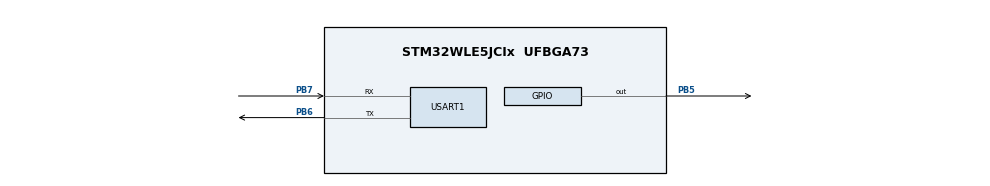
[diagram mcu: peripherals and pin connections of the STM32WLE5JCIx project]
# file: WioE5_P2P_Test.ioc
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Mcu.Family=STM32WL
Mcu.Name=STM32WLE5JCIx
Mcu.Package=UFBGA73
NVIC.PriorityGroup=NVIC_PRIORITYGROUP_4
NVIC.USART1_IRQn=true\:0\:0\:false\:false\:true\:true\:true\:true
PA13.Signal=DEBUG_JTMS-SWDIO
PA14.Signal=DEBUG_JTCK-SWCLK
PB5.Signal=GPIO_Output
PB6.Mode=Asynchronous
PB6.Signal=USART1_TX
PB7.Mode=Asynchronous
PB7.Signal=USART1_RX
ProjectManager.HeapSize=0x200
ProjectManager.StackSize=0x400
ProjectManager.TargetToolchain=STM32CubeIDE
RCC.HSE_VALUE=8000000
RCC.HSI_VALUE=16000000
RCC.LSE_VALUE=32768
RCC.VCOOutputFreq_Value=32000000
USART1.VirtualMode-Asynchronous=VM_ASYNC
board=custom

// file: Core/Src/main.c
/* USER CODE BEGIN Header */
/**
 ******************************************************************************
 * @file           : main.c
 * @brief          : Main program body
 ******************************************************************************
 * @attention
 *
 * Copyright (c) 2025 STMicroelectronics.
 * All rights reserved.
 *
 * This software is licensed under terms that can be found in the LICENSE file
 * in the root directory of this software component.
 * If no LICENSE file comes with this software, it is provided AS-IS.
 *
 ******************************************************************************
 */
/* USER CODE END Header */
#include "main.h"

UART_HandleTypeDef huart1;

/* USER CODE BEGIN PV */
uint8_t rx_data; // UARTで受信した1バイトのデータを格納する変数
/* USER CODE END PV */

void SystemClock_Config(void);
static void MX_GPIO_Init(void);
static void MX_USART1_UART_Init(void);

int main(void) {

	/* MCU Configuration--------------------------------------------------------*/

	/* Reset of all peripherals, Initializes the Flash interface and the Systick. */
	HAL_Init();

	/* Configure the system clock */
	SystemClock_Config();

	/* Initialize all configured peripherals */
	MX_GPIO_Init();
	MX_USART1_UART_Init();
	/* USER CODE BEGIN 2 */
	// 最初に一度だけ、UARTの割り込み受信を開始する
	HAL_UART_Receive_IT(&huart1, &rx_data, 1);
	/* USER CODE END 2 */

	/* Infinite loop */
	while (1) {
		HAL_GPIO_TogglePin(GPIOB, GPIO_PIN_5);
		// 1秒待つ
		HAL_Delay(500);
	}
}

void SystemClock_Config(void) {
	RCC_OscInitTypeDef RCC_OscInitStruct = { 0 };
	RCC_ClkInitTypeDef RCC_ClkInitStruct = { 0 };

	/** Configure the main internal regulator output voltage
	 */
	__HAL_PWR_VOLTAGESCALING_CONFIG(PWR_REGULATOR_VOLTAGE_SCALE2);

	/** Initializes the CPU, AHB and APB buses clocks
	 */
	RCC_OscInitStruct.OscillatorType = RCC_OSCILLATORTYPE_MSI;
	RCC_OscInitStruct.MSIState = RCC_MSI_ON;
	RCC_OscInitStruct.MSICalibrationValue = RCC_MSICALIBRATION_DEFAULT;
	RCC_OscInitStruct.MSIClockRange = RCC_MSIRANGE_6;
	RCC_OscInitStruct.PLL.PLLState = RCC_PLL_NONE;
	if (HAL_RCC_OscConfig(&RCC_OscInitStruct) != HAL_OK) {
		Error_Handler();
	}

	/** Configure the SYSCLKSource, HCLK, PCLK1 and PCLK2 clocks dividers
	 */
	RCC_ClkInitStruct.ClockType = RCC_CLOCKTYPE_HCLK3 | RCC_CLOCKTYPE_HCLK
			| RCC_CLOCKTYPE_SYSCLK | RCC_CLOCKTYPE_PCLK1 | RCC_CLOCKTYPE_PCLK2;
	RCC_ClkInitStruct.SYSCLKSource = RCC_SYSCLKSOURCE_MSI;
	RCC_ClkInitStruct.AHBCLKDivider = RCC_SYSCLK_DIV1;
	RCC_ClkInitStruct.APB1CLKDivider = RCC_HCLK_DIV1;
	RCC_ClkInitStruct.APB2CLKDivider = RCC_HCLK_DIV1;
	RCC_ClkInitStruct.AHBCLK3Divider = RCC_SYSCLK_DIV1;

	if (HAL_RCC_ClockConfig(&RCC_ClkInitStruct, FLASH_LATENCY_0) != HAL_OK) {
		Error_Handler();
	}
}

static void MX_USART1_UART_Init(void) {

	huart1.Instance = USART1;
	huart1.Init.BaudRate = 115200;
	huart1.Init.WordLength = UART_WORDLENGTH_8B;
	huart1.Init.StopBits = UART_STOPBITS_1;
	huart1.Init.Parity = UART_PARITY_NONE;
	huart1.Init.Mode = UART_MODE_TX_RX;
	huart1.Init.HwFlowCtl = UART_HWCONTROL_NONE;
	huart1.Init.OverSampling = UART_OVERSAMPLING_16;
	huart1.Init.OneBitSampling = UART_ONE_BIT_SAMPLE_DISABLE;
	huart1.Init.ClockPrescaler = UART_PRESCALER_DIV1;
	huart1.AdvancedInit.AdvFeatureInit = UART_ADVFEATURE_NO_INIT;
	if (HAL_UART_Init(&huart1) != HAL_OK) {
		Error_Handler();
	}
	if (HAL_UARTEx_SetTxFifoThreshold(&huart1, UART_TXFIFO_THRESHOLD_1_8)
			!= HAL_OK) {
		Error_Handler();
	}
	if (HAL_UARTEx_SetRxFifoThreshold(&huart1, UART_RXFIFO_THRESHOLD_1_8)
			!= HAL_OK) {
		Error_Handler();
	}
	if (HAL_UARTEx_DisableFifoMode(&huart1) != HAL_OK) {
		Error_Handler();
	}

}

static void MX_GPIO_Init(void) {
	GPIO_InitTypeDef GPIO_InitStruct = { 0 };

	/* GPIO Ports Clock Enable */
	__HAL_RCC_GPIOA_CLK_ENABLE();
	__HAL_RCC_GPIOB_CLK_ENABLE();

	/*Configure GPIO pin Output Level */
	HAL_GPIO_WritePin(GPIOB, GPIO_PIN_5, GPIO_PIN_RESET);

	/*Configure GPIO pin : PB5 */
	GPIO_InitStruct.Pin = GPIO_PIN_5;
	GPIO_InitStruct.Mode = GPIO_MODE_OUTPUT_PP;
	GPIO_InitStruct.Pull = GPIO_NOPULL;
	GPIO_InitStruct.Speed = GPIO_SPEED_FREQ_LOW;
	HAL_GPIO_Init(GPIOB, &GPIO_InitStruct);

}

/* USER CODE BEGIN 4 */
/**
 * @brief  UART受信完了コールバック関数
 * @param  huart UARTハンドル
 * @retval None
 */
void HAL_UART_RxCpltCallback(UART_HandleTypeDef *huart) {
	// どのUARTから割り込みがあったかを確認
	if (huart->Instance == USART1) {
		// 受信した文字に1を足した文字を送る
		// 例えば 'a' (ASCIIコード: 97) を受信したら 'b' (ASCIIコード: 98) を返す
		uint8_t tx_data = rx_data + 1;
		HAL_UART_Transmit(&huart1, &tx_data, 1, 100);

		// 再度、割り込み受信を開始する（これが非常に重要！）
		HAL_UART_Receive_IT(&huart1, &rx_data, 1);
	}
}
/* USER CODE END 4 */

void Error_Handler(void) {
	__disable_irq();
	while (1) {
	}
}
